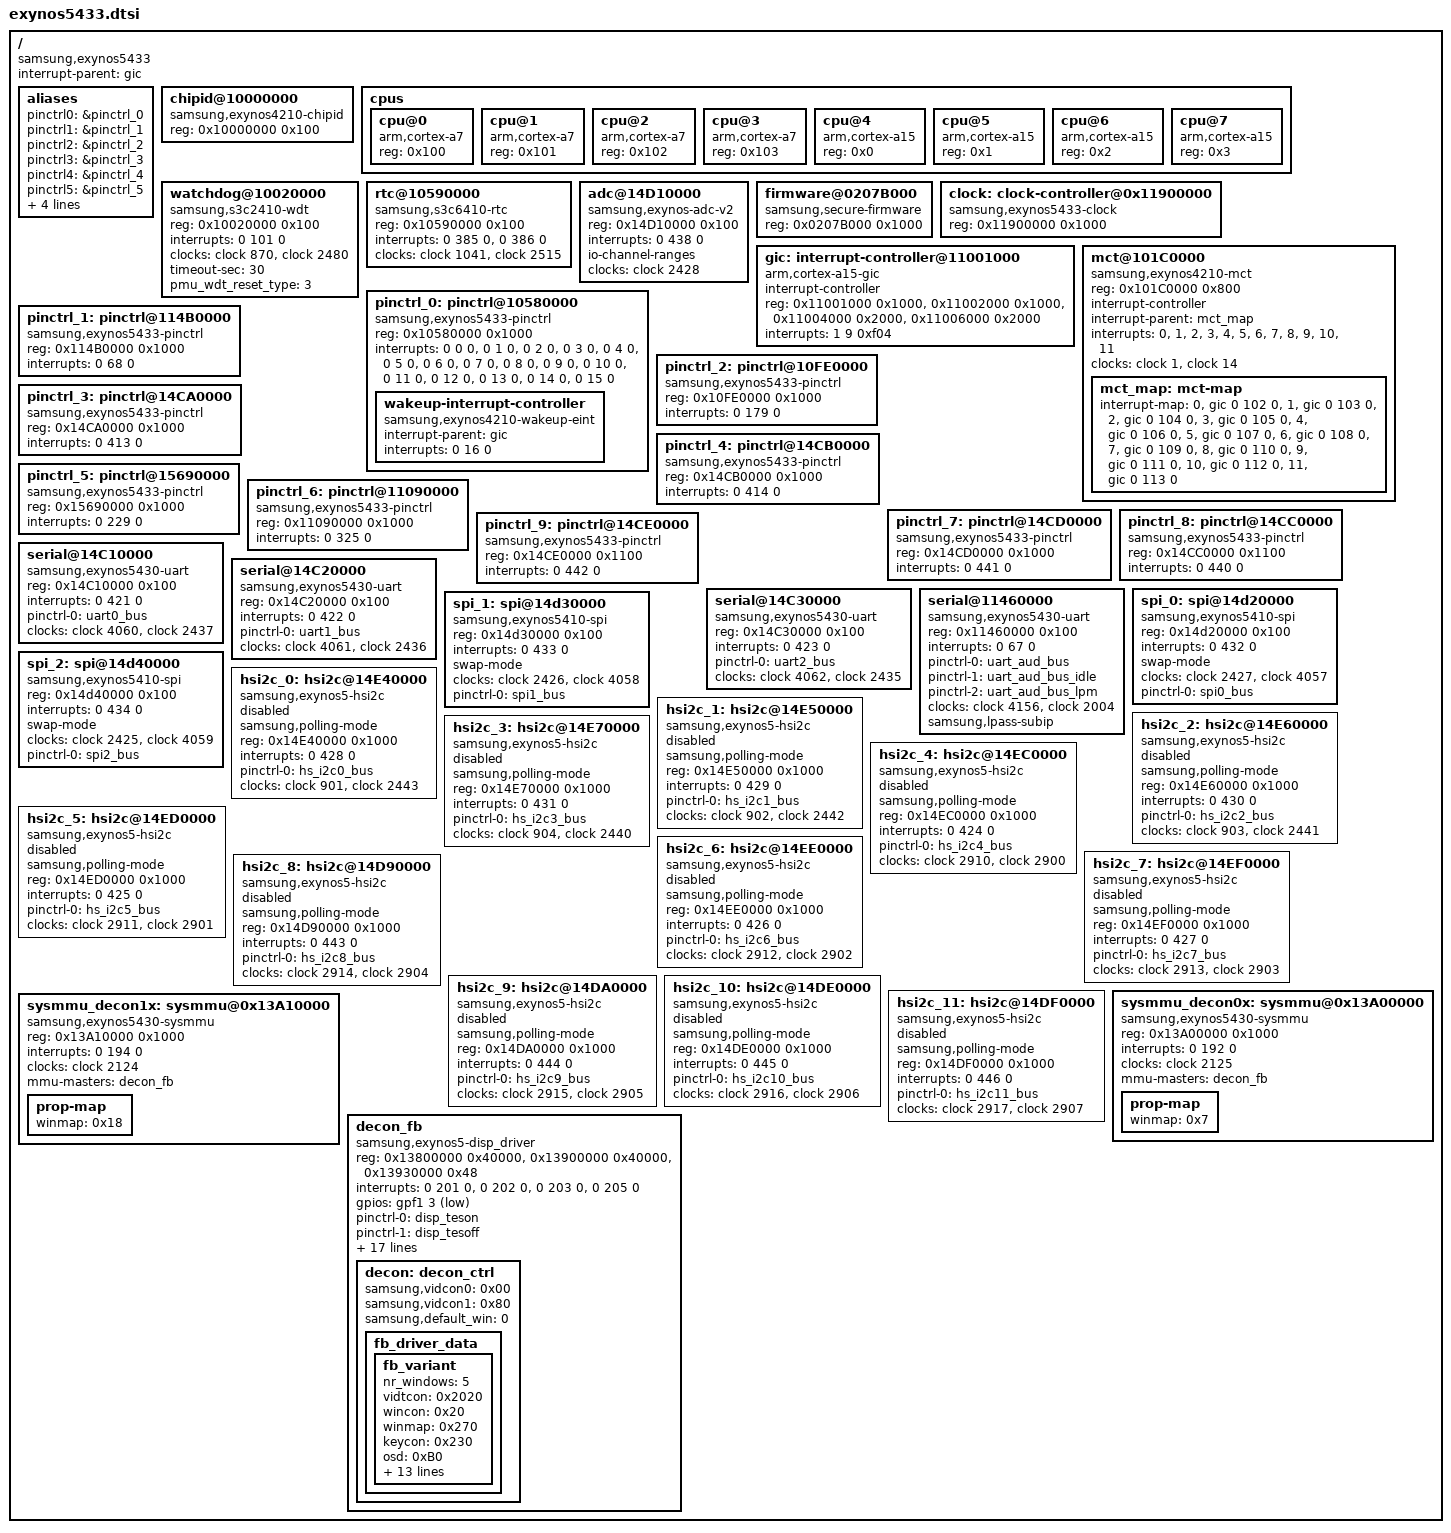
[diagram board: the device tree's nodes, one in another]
/*
 * SAMSUNG EXYNOS5433 SoC device tree source
 *
 * Copyright (c) 2013 Samsung Electronics Co., Ltd.
 *		http://www.samsung.com
 *
 * SAMSUNG EXYNOS5433 SoC device nodes are listed in this file.
 * EXYNOS5433 based board files can include this file and provide
 * values for board specfic bindings.
 *
 * This program is free software; you can redistribute it and/or modify
 * it under the terms of the GNU General Public License version 2 as
 * published by the Free Software Foundation.
 */

#include "skeleton.dtsi"
/include/ "exynos5433-pinctrl.dtsi"
/ {
	compatible = "samsung,exynos5433";

	interrupt-parent = <&gic>;

	aliases {
		pinctrl0 = &pinctrl_0;
		pinctrl1 = &pinctrl_1;
		pinctrl2 = &pinctrl_2;
		pinctrl3 = &pinctrl_3;
		pinctrl4 = &pinctrl_4;
		pinctrl5 = &pinctrl_5;
		pinctrl6 = &pinctrl_6;
		pinctrl7 = &pinctrl_7;
		pinctrl8 = &pinctrl_8;
		pinctrl9 = &pinctrl_9;
	};

	chipid@10000000 {
		compatible = "samsung,exynos4210-chipid";
		reg = <0x10000000 0x100>;
	};

	cpus {
		#address-cells = <1>;
		#size-cells = <0>;

		cpu@0 {
			device_type = "cpu";
			compatible = "arm,cortex-a7";
			reg = <0x100>;
		};
		cpu@1 {
			device_type = "cpu";
			compatible = "arm,cortex-a7";
			reg = <0x101>;
		};
		cpu@2 {
			device_type = "cpu";
			compatible = "arm,cortex-a7";
			reg = <0x102>;
		};
		cpu@3 {
			device_type = "cpu";
			compatible = "arm,cortex-a7";
			reg = <0x103>;
		};
		cpu@4 {
			device_type = "cpu";
			compatible = "arm,cortex-a15";
			reg = <0x0>;
		};
		cpu@5 {
			device_type = "cpu";
			compatible = "arm,cortex-a15";
			reg = <0x1>;
		};
		cpu@6 {
			device_type = "cpu";
			compatible = "arm,cortex-a15";
			reg = <0x2>;
		};
		cpu@7 {
			device_type = "cpu";
			compatible = "arm,cortex-a15";
			reg = <0x3>;
		};
	};

	watchdog@10020000 {
		compatible = "samsung,s3c2410-wdt";
		reg = <0x10020000 0x100>;
		interrupts = <0 101 0>;
		clocks = <&clock 870>, <&clock 2480>;
		clock-names = "rate_watchdog", "gate_watchdog";
		timeout-sec = <30>;
		pmu_wdt_reset_type = <3>;
	};

	rtc@10590000 {
		compatible = "samsung,s3c6410-rtc";
		reg = <0x10590000 0x100>;
		interrupts = <0 385 0>, <0 386 0>;
		clocks = <&clock 1041>, <&clock 2515>;
		clock-names = "rate_rtc", "gate_rtc";
	};

	adc@14D10000 {
		compatible = "samsung,exynos-adc-v2";
		reg = <0x14D10000 0x100>;
		interrupts = <0 438 0>;
		#io-channel-cells = <1>;
		io-channel-ranges;
		clocks = <&clock 2428>;
		clock-names = "gate_adcif";
	};

	firmware@0207B000 {
		compatible = "samsung,secure-firmware";
		reg = <0x0207B000 0x1000>;
	};
	clock: clock-controller@0x11900000 {
		compatible = "samsung,exynos5433-clock";
		reg = <0x11900000 0x1000>;
		#clock-cells = <1>;
	};

	gic:interrupt-controller@11001000 {
		compatible = "arm,cortex-a15-gic";
		#interrupt-cells = <3>;
		interrupt-controller;
		reg =	<0x11001000 0x1000>,
			<0x11002000 0x1000>,
			<0x11004000 0x2000>,
			<0x11006000 0x2000>;
		interrupts = <1 9 0xf04>;
	};

	mct@101C0000 {
		compatible = "samsung,exynos4210-mct";
		reg = <0x101C0000 0x800>;
		interrupt-controller;
		#interrupt-cells = <1>;
		interrupt-parent = <&mct_map>;
		interrupts =	<0>, <1>, <2>, <3>,
				<4>, <5>, <6>, <7>,
				<8>, <9>, <10>, <11>;
		clocks = <&clock 1>, <&clock 14>;
		clock-names = "fin_pll", "mct";

		mct_map: mct-map {
			#interrupt-cells = <1>;
			#address-cells = <0>;
			#size-cells = <0>;
			interrupt-map = <0 &gic 0 102 0>,
					<1 &gic 0 103 0>,
					<2 &gic 0 104 0>,
					<3 &gic 0 105 0>,
					<4 &gic 0 106 0>,
					<5 &gic 0 107 0>,
					<6 &gic 0 108 0>,
					<7 &gic 0 109 0>,
					<8 &gic 0 110 0>,
					<9 &gic 0 111 0>,
					<10 &gic 0 112 0>,
					<11 &gic 0 113 0>;
		};
	};

	pinctrl_0: pinctrl@10580000 {
		compatible = "samsung,exynos5433-pinctrl";
		reg = <0x10580000 0x1000>;
		interrupts = <0 0 0>, <0 1 0>, <0 2 0>, <0 3 0>,
			     <0 4 0>, <0 5 0>, <0 6 0>, <0 7 0>,
			     <0 8 0>, <0 9 0>, <0 10 0>, <0 11 0>,
			     <0 12 0>, <0 13 0>, <0 14 0>, <0 15 0>;
		wakeup-interrupt-controller {
			compatible = "samsung,exynos4210-wakeup-eint";
			interrupt-parent = <&gic>;
			interrupts = <0 16 0>;
		};
	};

	pinctrl_1: pinctrl@114B0000 {
		compatible = "samsung,exynos5433-pinctrl";
		reg = <0x114B0000 0x1000>;
		interrupts = <0 68 0>;
	};

	pinctrl_2: pinctrl@10FE0000 {
		compatible = "samsung,exynos5433-pinctrl";
		reg = <0x10FE0000 0x1000>;
		interrupts = <0 179 0>;
	};

	pinctrl_3: pinctrl@14CA0000 {
		compatible = "samsung,exynos5433-pinctrl";
		reg = <0x14CA0000 0x1000>;
		interrupts = <0 413 0>;
	};

	pinctrl_4: pinctrl@14CB0000 {
		compatible = "samsung,exynos5433-pinctrl";
		reg = <0x14CB0000 0x1000>;
		interrupts = <0 414 0>;
	};

	pinctrl_5: pinctrl@15690000 {
		compatible = "samsung,exynos5433-pinctrl";
		reg = <0x15690000 0x1000>;
		interrupts = <0 229 0>;
	};

	pinctrl_6: pinctrl@11090000 {
		compatible = "samsung,exynos5433-pinctrl";
		reg = <0x11090000 0x1000>;
		interrupts = <0 325 0>;
	};

	pinctrl_7: pinctrl@14CD0000 {
		compatible = "samsung,exynos5433-pinctrl";
		reg = <0x14CD0000 0x1000>;
		interrupts = <0 441 0>;
	};

	pinctrl_8: pinctrl@14CC0000 {
		compatible = "samsung,exynos5433-pinctrl";
		reg = <0x14CC0000 0x1100>;
		interrupts = <0 440 0>;
	};

	pinctrl_9: pinctrl@14CE0000 {
		compatible = "samsung,exynos5433-pinctrl";
		reg = <0x14CE0000 0x1100>;
		interrupts = <0 442 0>;
	};

	serial@14C10000 {
		compatible = "samsung,exynos5430-uart";
		reg = <0x14C10000 0x100>;
		interrupts = <0 421 0>;
		pinctrl-names = "default";
		pinctrl-0 = <&uart0_bus>;
		clocks = <&clock 4060>, <&clock 2437>;
		clock-names = "sclk_uart0", "gate_uart0";
	};

	serial@14C20000 {
		compatible = "samsung,exynos5430-uart";
		reg = <0x14C20000 0x100>;
		interrupts = <0 422 0>;
		pinctrl-names = "default";
		pinctrl-0 = <&uart1_bus>;
		clocks = <&clock 4061>, <&clock 2436>;
		clock-names = "sclk_uart1", "gate_uart1";
	};

	serial@14C30000 {
		compatible = "samsung,exynos5430-uart";
		reg = <0x14C30000 0x100>;
		interrupts = <0 423 0>;
		pinctrl-names = "default";
		pinctrl-0 = <&uart2_bus>;
		clocks = <&clock 4062>, <&clock 2435>;
		clock-names = "sclk_uart2", "gate_uart2";
	};

	serial@11460000 {
		compatible = "samsung,exynos5430-uart";
		reg = <0x11460000 0x100>;
		interrupts = <0 67 0>;
		pinctrl-names = "default", "idle", "lpm";
		pinctrl-0 = <&uart_aud_bus>;
		pinctrl-1 = <&uart_aud_bus_idle>;
		pinctrl-2 = <&uart_aud_bus_lpm>;
		clocks = <&clock 4156>, <&clock 2004>;
		clock-names = "sclk_uart3", "gate_uart3";
		samsung,lpass-subip;
	};

	spi_0: spi@14d20000 {
		compatible = "samsung,exynos5410-spi";
		reg = <0x14d20000 0x100>;
		interrupts = <0 432 0>;
		swap-mode;
		#address-cells = <1>;
		#size-cells = <0>;
		clocks = <&clock 2427>, <&clock 4057>;
		clock-names = "spi", "spi_busclk0";
		pinctrl-names = "default";
		pinctrl-0 = <&spi0_bus>;
	};

	spi_1: spi@14d30000 {
		compatible = "samsung,exynos5410-spi";
		reg = <0x14d30000 0x100>;
		interrupts = <0 433 0>;
		swap-mode;
		#address-cells = <1>;
		#size-cells = <0>;
		clocks = <&clock 2426>, <&clock 4058>;
		clock-names = "spi", "spi_busclk0";
		pinctrl-names = "default";
		pinctrl-0 = <&spi1_bus>;
	};

	spi_2: spi@14d40000 {
		compatible = "samsung,exynos5410-spi";
		reg = <0x14d40000 0x100>;
		interrupts = <0 434 0>;
		swap-mode;
		#address-cells = <1>;
		#size-cells = <0>;
		clocks = <&clock 2425>, <&clock 4059>;
		clock-names = "spi", "spi_busclk0";
		pinctrl-names = "default";
		pinctrl-0 = <&spi2_bus>;
	};

	hsi2c_0: hsi2c@14E40000 {
		compatible = "samsung,exynos5-hsi2c";
		samsung,polling-mode;
		reg = <0x14E40000 0x1000>;
		interrupts = <0 428 0>;
		#address-cells = <1>;
		#size-cells = <0>;
		pinctrl-names = "default";
		pinctrl-0 = <&hs_i2c0_bus>;
		clocks = <&clock 901>, <&clock 2443>;
		clock-names = "rate_hsi2c", "gate_hsi2c";
		status = "disabled";
	};

	hsi2c_1: hsi2c@14E50000 {
		compatible = "samsung,exynos5-hsi2c";
		samsung,polling-mode;
		reg = <0x14E50000 0x1000>;
		interrupts = <0 429 0>;
		#address-cells = <1>;
		#size-cells = <0>;
		pinctrl-names = "default";
		pinctrl-0 = <&hs_i2c1_bus>;
		clocks = <&clock 902>, <&clock 2442>;
		clock-names = "rate_hsi2c", "gate_hsi2c";
		status = "disabled";
	};

	hsi2c_2: hsi2c@14E60000 {
		compatible = "samsung,exynos5-hsi2c";
		samsung,polling-mode;
		reg = <0x14E60000 0x1000>;
		interrupts = <0 430 0>;
		#address-cells = <1>;
		#size-cells = <0>;
		pinctrl-names = "default";
		pinctrl-0 = <&hs_i2c2_bus>;
		clocks = <&clock 903>, <&clock 2441>;
		clock-names = "rate_hsi2c", "gate_hsi2c";
		status = "disabled";
	};

	hsi2c_3: hsi2c@14E70000 {
		compatible = "samsung,exynos5-hsi2c";
		samsung,polling-mode;
		reg = <0x14E70000 0x1000>;
		interrupts = <0 431 0>;
		#address-cells = <1>;
		#size-cells = <0>;
		pinctrl-names = "default";
		pinctrl-0 = <&hs_i2c3_bus>;
		clocks = <&clock 904>, <&clock 2440>;
		clock-names = "rate_hsi2c", "gate_hsi2c";
		status = "disabled";
	};

	hsi2c_4: hsi2c@14EC0000 {
		compatible = "samsung,exynos5-hsi2c";
		samsung,polling-mode;
		reg = <0x14EC0000 0x1000>;
		interrupts = <0 424 0>;
		#address-cells = <1>;
		#size-cells = <0>;
		pinctrl-names = "default";
		pinctrl-0 = <&hs_i2c4_bus>;
		clocks = <&clock 2910>, <&clock 2900>;
		clock-names = "rate_hsi2c", "gate_hsi2c";
		status = "disabled";
	};

	hsi2c_5: hsi2c@14ED0000 {
		compatible = "samsung,exynos5-hsi2c";
		samsung,polling-mode;
		reg = <0x14ED0000 0x1000>;
		interrupts = <0 425 0>;
		#address-cells = <1>;
		#size-cells = <0>;
		pinctrl-names = "default";
		pinctrl-0 = <&hs_i2c5_bus>;
		clocks = <&clock 2911>, <&clock 2901>;
		clock-names = "rate_hsi2c", "gate_hsi2c";
		status = "disabled";
	};

	hsi2c_6: hsi2c@14EE0000 {
		compatible = "samsung,exynos5-hsi2c";
		samsung,polling-mode;
		reg = <0x14EE0000 0x1000>;
		interrupts = <0 426 0>;
		#address-cells = <1>;
		#size-cells = <0>;
		pinctrl-names = "default";
		pinctrl-0 = <&hs_i2c6_bus>;
		clocks = <&clock 2912>, <&clock 2902>;
		clock-names = "rate_hsi2c", "gate_hsi2c";
		status = "disabled";
	};

	hsi2c_7: hsi2c@14EF0000 {
		compatible = "samsung,exynos5-hsi2c";
		samsung,polling-mode;
		reg = <0x14EF0000 0x1000>;
		interrupts = <0 427 0>;
		#address-cells = <1>;
		#size-cells = <0>;
		pinctrl-names = "default";
		pinctrl-0 = <&hs_i2c7_bus>;
		clocks = <&clock 2913>, <&clock 2903>;
		clock-names = "rate_hsi2c", "gate_hsi2c";
		status = "disabled";
	};

	hsi2c_8: hsi2c@14D90000 {
		compatible = "samsung,exynos5-hsi2c";
		samsung,polling-mode;
		reg = <0x14D90000 0x1000>;
		interrupts = <0 443 0>;
		#address-cells = <1>;
		#size-cells = <0>;
		pinctrl-names = "default";
		pinctrl-0 = <&hs_i2c8_bus>;
		clocks = <&clock 2914>, <&clock 2904>;
		clock-names = "rate_hsi2c", "gate_hsi2c";
		status = "disabled";
	};

	hsi2c_9: hsi2c@14DA0000 {
		compatible = "samsung,exynos5-hsi2c";
		samsung,polling-mode;
		reg = <0x14DA0000 0x1000>;
		interrupts = <0 444 0>;
		#address-cells = <1>;
		#size-cells = <0>;
		pinctrl-names = "default";
		pinctrl-0 = <&hs_i2c9_bus>;
		clocks = <&clock 2915>, <&clock 2905>;
		clock-names = "rate_hsi2c", "gate_hsi2c";
		status = "disabled";
	};

	hsi2c_10: hsi2c@14DE0000 {
		compatible = "samsung,exynos5-hsi2c";
		samsung,polling-mode;
		reg = <0x14DE0000 0x1000>;
		interrupts = <0 445 0>;
		#address-cells = <1>;
		#size-cells = <0>;
		pinctrl-names = "default";
		pinctrl-0 = <&hs_i2c10_bus>;
		clocks = <&clock 2916>, <&clock 2906>;
		clock-names = "rate_hsi2c", "gate_hsi2c";
		status = "disabled";
	};

	hsi2c_11: hsi2c@14DF0000 {
		compatible = "samsung,exynos5-hsi2c";
		samsung,polling-mode;
		reg = <0x14DF0000 0x1000>;
		interrupts = <0 446 0>;
		#address-cells = <1>;
		#size-cells = <0>;
		pinctrl-names = "default";
		pinctrl-0 = <&hs_i2c11_bus>;
		clocks = <&clock 2917>, <&clock 2907>;
		clock-names = "rate_hsi2c", "gate_hsi2c";
		status = "disabled";
	};

	sysmmu_decon0x: sysmmu@0x13A00000 {
		compatible = "samsung,exynos5430-sysmmu";
		reg = <0x13A00000 0x1000>;
		interrupts = <0 192 0>;
		clock-names = "sysmmu";
		clocks = <&clock 2125>;
		mmu-masters = <&decon_fb>;
		prop-map {
			winmap = <0x7>;
		};
	};

	sysmmu_decon1x: sysmmu@0x13A10000 {
		compatible = "samsung,exynos5430-sysmmu";
		reg = <0x13A10000 0x1000>;
		interrupts = <0 194 0>;
		clock-names = "sysmmu";
		clocks = <&clock 2124>;
		mmu-masters = <&decon_fb>;
		prop-map {
			winmap = <0x18>;
		};
	};

	/* disp_driver */
	decon_fb: decon_fb {
		compatible = "samsung,exynos5-disp_driver";

		reg = <0x13800000 0x40000>, <0x13900000 0x40000>, <0x13930000 0x48>;

		/*samsung,power-domain = <&spd_decon>;*/

		/* interrupt num */
		interrupts = <0 201 0>, <0 202 0>, <0 203 0>, <0 205 0>;

		/* GPIO & pin control */
		gpios = <&gpf1 3 0xf>;

		pinctrl-names = "turnon_tes", "turnoff_tes";
		pinctrl-0 = <&disp_teson>;
		pinctrl-1 = <&disp_tesoff>;

		clock-names =
			"gate_dsd", "gate_decon", "gate_mic", "gate_dsim0",
			"aclk_disp_333", "dout_aclk_disp_333", "dout_mfc_pll", "dout_pclk_disp",
			"dout_sclk_dsd", "mout_sclk_dsd_c", "mout_sclk_dsd_b", "mout_sclk_dsd_a",
			"mout_mfc_pll_div2", "mout_sclk_dsd_user", "sclk_dsd_disp",
			"dout_sclk_decon_eclk", "dout_sclk_decon_eclk_disp", "dout_sclk_decon_vclk", "dout_sclk_decon_vclk_disp",
			"dout_sclk_dsim0", "dout_sclk_dsim0_disp",
			"mout_aclk_disp_333_a", "mout_aclk_disp_333_b", "mout_aclk_disp_333_user", "mout_bus_pll_div2",
			"mout_disp_pll", "mout_mfc_pll_div2", "mout_sclk_decon_eclk", "mout_sclk_decon_eclk_a",
			"mout_sclk_decon_eclk_b", "mout_sclk_decon_eclk_c", "mout_sclk_decon_eclk_user",
			"mout_sclk_decon_vclk", "mout_sclk_decon_vclk_a", "mout_sclk_decon_vclk_b", "mout_sclk_decon_vclk_c",
			"mout_sclk_decon_vclk_user", "mout_sclk_dsd_a", "mout_sclk_dsd_user", "mout_sclk_dsim0",
			"mout_sclk_dsim0_a", "mout_sclk_dsim0_b", "mout_sclk_dsim0_c", "mout_sclk_dsim0_user",
			"oscclk", "sclk_decon_eclk_disp",
			"sclk_dsim0_disp",
			"mout_phyclk_mipidphy_rxclkesc0_user", "phyclk_mipidphy_rxclkesc0_phy",
			"mout_phyclk_mipidphy_bitclkdiv8_user", "phyclk_mipidphy_bitclkdiv8_phy",
			"disp_pll";

		clocks =
			/*gate_dsd*/ <&clock 2103>, /*gate_decon*/ <&clock 2114>, /*gate_mic*/ <&clock 2104>, /*gate_dsim0*/ <&clock 2110>,
			/*aclk_disp_333*/ <&clock 321>, /*dout_aclk_disp_333*/ <&clock 4116>, /*dout_mfc_pll*/ <&clock 4102>, /*dout_pclk_disp*/ <&clock 4140>,
			/*dout_sclk_dsd*/ <&clock 4119>, /*mout_sclk_dsd_c*/ <&clock 3102>, /*mout_sclk_dsd_b*/ <&clock 3101>, /*mout_sclk_dsd_a*/ <&clock 3100>,
			/*mout_mfc_pll_div2*/ <&clock 3242>, /*mout_sclk_dsd_user*/ <&clock 3134>, /*sclk_dsd_disp*/ <&clock 83>,

			/*dout_sclk_decon_eclk*/ <&clock 4117>, /*dout_sclk_decon_eclk_disp*/ <&clock 4141>, /*dout_sclk_decon_vclk*/ <&clock 4118>, /*dout_sclk_decon_vclk_disp*/ <&clock 4142>,
			/*dout_sclk_dsim0*/ <&clock 4201>, /*dout_sclk_dsim0_disp*/ <&clock 4144>,
			/*mout_aclk_disp_333_a*/ <&clock 3086>, /*mout_aclk_disp_333_b*/ <&clock 3087>, /*mout_aclk_disp_333_user*/ <&clock 3125>, /*mout_bus_pll_div2*/ <&clock 3243>,
			/*mout_disp_pll*/ <&clock 3124>, /*mout_mfc_pll_div2*/ <&clock 3242>, /*mout_sclk_decon_eclk*/ <&clock 3131>, /*mout_sclk_decon_eclk_a*/ <&clock 3090>,
			/*mout_sclk_decon_eclk_b*/ <&clock 3091>, /*mout_sclk_decon_eclk_c*/ <&clock 3092>, /*mout_sclk_decon_eclk_user*/ <&clock 3130>,
			/*mout_sclk_decon_vclk*/ <&clock 3133>, /*mout_sclk_decon_vclk_a*/ <&clock 3093>, /*mout_sclk_decon_vclk_b*/ <&clock 3094>, /*mout_sclk_decon_vclk_c*/ <&clock 3095>,
			/*mout_sclk_decon_vclk_user*/ <&clock 3132>, /*mout_sclk_dsd_a*/ <&clock 3100>, /*mout_sclk_dsd_user*/ <&clock 3134>, /*mout_sclk_dsim0*/ <&clock 3269>,
			/*mout_sclk_dsim0_a*/ <&clock 3263>, /*mout_sclk_dsim0_b*/ <&clock 3264>, /*mout_sclk_dsim0_c*/ <&clock 3265>, /*mout_sclk_dsim0_user*/ <&clock 3268>,
			/*oscclk*/ <&clock 5000>, /*sclk_decon_eclk_disp*/ <&clock 81>, /*sclk_dsim0_disp*/ <&clock 85>,
			/*mout_phyclk_mipidphy_rxclkesc0_user*/ <&clock 3137>, /*phyclk_mipidphy_rxclkesc0_phy*/ <&clock 5025>,
			/*mout_phyclk_mipidphy_bitclkdiv8_user*/ <&clock 3138>, /*phyclk_mipidphy_bitclkdiv8_phy*/ <&clock 5026>,
			/*disp_pll*/ <&clock 7>;

		decon: decon_ctrl {
			samsung,vidcon0 = <0x00>;
			samsung,vidcon1 = <0x80>;
			samsung,default_win = <0>;

			fb_driver_data {
				fb_variant {
					nr_windows = <5>;
					vidtcon = <0x2020>;
					wincon = <0x20>;
					winmap = <0x270>;
					keycon = <0x230>;
					osd = <0xB0>;
					osd_stride = <16>;
					buf_start = <0x150>;
					buf_size  = <0x200>;
					buf_end   = <0x1A0>;
					palette_0 = <0x2400>;
					palette_1 = <0x2800>;
					palette_2 = <0x2c00>;
					palette_3 = <0x3000>;
					palette_4 = <0x3400>;
					has_shadowcon = <1>;
					has_blendcon  = <1>;
					has_alphacon  = <1>;
					has_fixvclk   = <1>;
				};
			};
		};
	};

};
